# CY8C4245AXI_483 register map
File version: 0.1
CY8C42
Registers are 32-bit, read-write, no defined reset value unless marked. A register's access mark holds for its fields unless they carry their own. Offsets are from the block's base; lines under a group give offsets from that group; [hi:lo] are bit positions; {n}, {i} and the like mark numbered series; 'fields as' and 'values as' point back to an identical list; <NAME> marks a mode.

## Memory map
0x40060000 usbUART115200bps size 0xFCD — Serial Communication Block
0x400F0003 TIMER_ThreadTimer size 0x91
0x400F0021 PWM_LEFT size 0x71
0x400F0022 PWM_RIGHT size 0x71
0x400F0071 controlRegStep size 0x1

## TIMER_ThreadTimer
Base 0x400F0003
0x00 TIMER_ThreadTimer_COUNTER 8-bit — UDB.A0 - Current Down Counter Value
0x20 TIMER_ThreadTimer_PERIOD 8-bit — UDB.D0 - Assigned Period
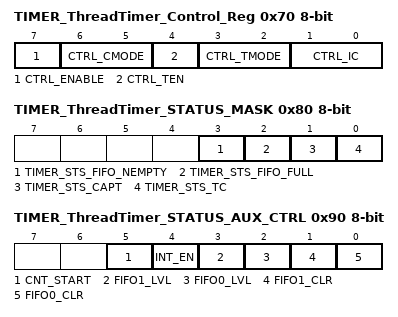
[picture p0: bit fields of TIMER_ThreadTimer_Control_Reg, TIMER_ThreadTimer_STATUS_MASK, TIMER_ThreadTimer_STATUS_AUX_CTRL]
0x70 TIMER_ThreadTimer_Control_Reg 8-bit — UDB Control Register - Assigned Control Register Value
  [7] CTRL_ENABLE — Enable the Timer
  [6:5] CTRL_CMODE — Capture Mode
  [4] CTRL_TEN — Trigger Enable Bit
  [3:2] CTRL_TMODE — Trigger Mode
  [1:0] CTRL_IC — Interrupt Count
0x80 TIMER_ThreadTimer_STATUS_MASK 8-bit — UDB Status bits Interrupt Mask Enable Register
  [3] TIMER_STS_FIFO_NEMPTY ro — FIFO Empty status
  [2] TIMER_STS_FIFO_FULL ro — FIFO Full Status
  [1] TIMER_STS_CAPT ro — Enables the Interrupt on Capture
  [0] TIMER_STS_TC ro — Enables the Interrupt on TC
0x90 TIMER_ThreadTimer_STATUS_AUX_CTRL 8-bit — UDB Auxilliary Control Register
  [5] CNT_START — FIFO0 clear
    0=E_CNT_START0 (Disable counter); 1=E_CNT_START1 (Enable counter)
  [4] INT_EN
    0=E_INT_EN0 (Interrupt disabled); 1=E_INT_EN1 (Interrupt enabled)
  [3] FIFO1_LVL — FIFO level
    0=E_FIFO_LVL_0 (FIFO LVL: input mode: FIFO not full; output mode: FIFO not empty); 1=E_FIFO_LVL_1 (FIFO LVL: input mode: FIFO at least 1/2 empty; output mode: FIFO at least 1/2 full)
  [2] FIFO0_LVL — FIFO level
    values as FIFO1_LVL
  [1] FIFO1_CLR — FIFO1 clear
    0=E_FIFO_CLR_0 (Normal FIFO operation); 1=E_FIFO_CLR_1 (Clear FIFO state)
  [0] FIFO0_CLR — FIFO0 clear
    values as FIFO1_CLR

## PWM_LEFT
Base 0x400F0021
0x00 PWM_LEFT_COMPARE_Reg_ 8-bit — UDB.D0 - Assigned Compare Value
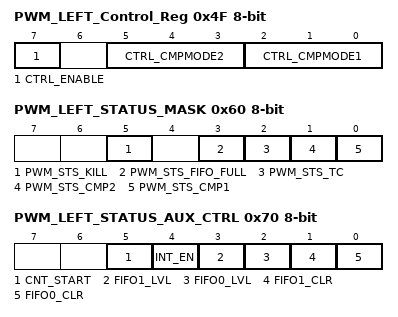
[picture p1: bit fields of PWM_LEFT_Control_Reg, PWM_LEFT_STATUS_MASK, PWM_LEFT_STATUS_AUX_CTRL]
0x4F PWM_LEFT_Control_Reg 8-bit — UDB Control Register - Assigned Control Register Value
  [7] CTRL_ENABLE — Enable the PWM
  [5:3] CTRL_CMPMODE2 — Compare mode 2
  [2:0] CTRL_CMPMODE1 — Compare mode 1
0x60 PWM_LEFT_STATUS_MASK 8-bit — UDB Status bits Interrupt Mask Enable Register
  [5] PWM_STS_KILL ro — Enables the Interrupt on Kill
  [3] PWM_STS_FIFO_FULL ro — FIFO Full Status Mask
  [2] PWM_STS_TC ro — Enables the Interrupt on Terminal Count
  [1] PWM_STS_CMP2 ro — Enables the Interrupt on Compare 2
  [0] PWM_STS_CMP1 ro — Enables the Interrupt on Compare 1
0x70 PWM_LEFT_STATUS_AUX_CTRL 8-bit — UDB Auxilliary Control Register
  [5] CNT_START — FIFO0 clear
    0=E_CNT_START0 (Disable counter); 1=E_CNT_START1 (Enable counter)
  [4] INT_EN
    0=E_INT_EN0 (Interrupt disabled); 1=E_INT_EN1 (Interrupt enabled)
  [3] FIFO1_LVL — FIFO level
    0=E_FIFO_LVL_0 (FIFO LVL: input mode: FIFO not full; output mode: FIFO not empty); 1=E_FIFO_LVL_1 (FIFO LVL: input mode: FIFO at least 1/2 empty; output mode: FIFO at least 1/2 full)
  [2] FIFO0_LVL — FIFO level
    values as FIFO1_LVL
  [1] FIFO1_CLR — FIFO1 clear
    0=E_FIFO_CLR_0 (Normal FIFO operation); 1=E_FIFO_CLR_1 (Clear FIFO state)
  [0] FIFO0_CLR — FIFO0 clear
    values as FIFO1_CLR

## PWM_RIGHT
Base 0x400F0022
Registers as PWM_LEFT (with PWM_LEFT read as PWM_RIGHT), without PWM_LEFT_Control_Reg; these are added or differ:
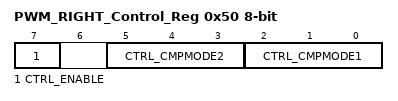
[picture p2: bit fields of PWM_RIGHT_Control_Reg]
0x50 PWM_RIGHT_Control_Reg 8-bit — UDB Control Register - Assigned Control Register Value
  [7] CTRL_ENABLE — Enable the PWM
  [5:3] CTRL_CMPMODE2 — Compare mode 2
  [2:0] CTRL_CMPMODE1 — Compare mode 1

## controlRegStep
Base 0x400F0071
0x00 controlRegStep_CONTROL_REG 8-bit
